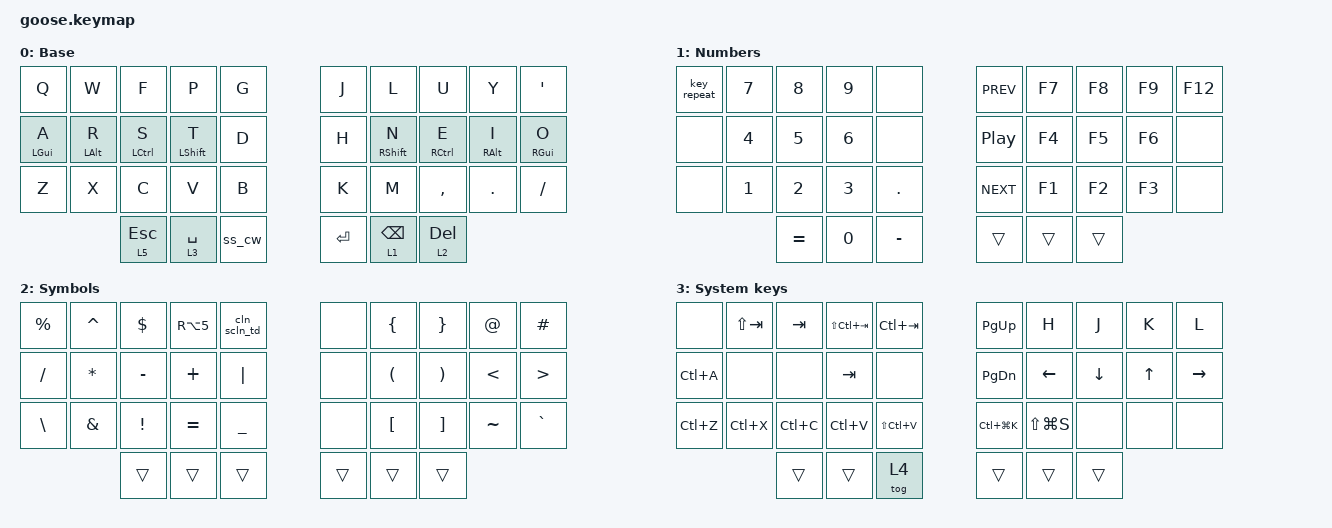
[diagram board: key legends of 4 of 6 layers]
#include <behaviors.dtsi>
#include <dt-bindings/zmk/keys.h>
#include <dt-bindings/zmk/bt.h>

// Home row mods settings

// Speed without triggering modifier
#define TAPPING_RESOLUTION 100

// Hold time for tap-preferred behavior
#define HOLD_TYPE "tap-preferred"

// Time to wait after typing before mods are available
#define STREAK_DECAY (TAPPING_RESOLUTION + 100)

// Time to auto-repeat key
#define REPEAT_DECAY (TAPPING_RESOLUTION + 100)

// Time to trigger layer
#define LAYER_HOLD_TIME (TAPPING_RESOLUTION + 50)

// Time to trigger home row mods
#define HRM_HOLD_TIME (TAPPING_RESOLUTION + 50)

// Time to trigger tap dance
#define TAP_DANCE_TIME (TAPPING_RESOLUTION + 100)

// Idle time before sticky keys are released
#define IDLE_TIMEOUT_MS 7500

&lt {
    // Layer toggle
    flavor = HOLD_TYPE;
    tapping-term-ms = <LAYER_HOLD_TIME>;
    quick-tap-ms = <REPEAT_DECAY>;
};
&sk {
    // Sticky keys settings, One Shot Keys [QMK]

    release-after-ms = <IDLE_TIMEOUT_MS>;
    quick-release;
};
&caps_word {
    // Allow caps word to continue even when minus or underscore are pressed.
    // Also prevent mod presses from cancelling caps word.

    continue-list = <
      UNDERSCORE MINUS
      LCTRL LALT LGUI LSHFT
      RCTRL RALT RGUI RSHFT
      BACKSPACE
    >;

    /delete-property/ ignore-modifiers;
};
/ {
    behaviors {
        hrm: homerow_mods {
            compatible = "zmk,behavior-hold-tap";
            flavor = HOLD_TYPE;

            #binding-cells = <2>;
            bindings = <&kp>, <&kp>;

            tapping-term-ms = <HRM_HOLD_TIME>;
            quick-tap-ms = <REPEAT_DECAY>;
            require-prior-idle-ms = <STREAK_DECAY>;
        };
        hrmralt: homerow_mods_ralt {
            compatible = "zmk,behavior-hold-tap";
            flavor = HOLD_TYPE;

            #binding-cells = <2>;
            bindings = <&kp>, <&kp>;

            tapping-term-ms = <HRM_HOLD_TIME>;
            quick-tap-ms = <REPEAT_DECAY>;
            require-prior-idle-ms = <(TAPPING_RESOLUTION + 25)>;
        };

        ss_cw: shift_capsword {
            compatible = "zmk,behavior-tap-dance";
            #binding-cells = <0>;
            bindings = <&sk LEFT_SHIFT>, <&caps_word>;

            tapping-term-ms = <TAP_DANCE_TIME>;
        };

        cln_scln_td: cln_scln_td {
            compatible = "zmk,behavior-tap-dance";
            #binding-cells = <0>;
            bindings = <&kp COLON>, <&kp SEMICOLON>;
        };

    };

    keymap {
        compatible = "zmk,keymap";

        base {
            display-name = "Base";
            bindings = <
                &kp Q            &kp W            &kp F                &kp P              &kp G   &kp J      &kp L               &kp U                 &kp Y             &kp SINGLE_QUOTE
                &hrm LEFT_GUI A  &hrm LEFT_ALT R  &hrm LEFT_CONTROL S  &hrm LEFT_SHIFT T  &kp D   &kp H      &hrm RIGHT_SHIFT N  &hrm RIGHT_CONTROL E  &hrmralt RIGHT_ALT I  &hrm RIGHT_GUI O
                &kp Z            &kp X            &kp C                &kp V              &kp B   &kp K      &kp M               &kp COMMA            &kp DOT          &kp SLASH
                                                  &lt 5 ESC            &lt 3 SPACE        &ss_cw  &kp ENTER  &lt 1 BACKSPACE     &lt 2 DELETE
            >;

            sensor-bindings =
                <&inc_dec_kp C_VOL_UP C_VOLUME_DOWN>,
                <&inc_dec_kp PG_UP PAGE_DOWN>;
        };

        num_fun {
            display-name = "Numbers";
            bindings = <
                &key_repeat  &kp N7  &kp N8     &kp N9  &none      &kp C_PREV  &kp F7  &kp F8  &kp F9  &kp F12
                &none        &kp N4  &kp N5     &kp N6  &none      &kp C_PP    &kp F4  &kp F5  &kp F6  &none
                &none        &kp N1  &kp N2     &kp N3  &kp DOT    &kp C_NEXT  &kp F1  &kp F2  &kp F3  &none
                                    &kp EQUAL  &kp N0  &kp MINUS  &trans      &trans  &trans
            >;

            sensor-bindings = <&inc_dec_kp LC(Z) LC(Y)>;
        };

        sym_uti {
            display-name = "Symbols";
            bindings = <
                &kp PERCENT  &kp CARET      &kp DOLLAR       &kp RA(N5)  &cln_scln_td    &none   &kp LEFT_BRACE        &kp RIGHT_BRACE        &kp AT_SIGN    &kp HASH
                &kp FSLH     &kp ASTERISK   &kp MINUS        &kp PLUS    &kp PIPE        &none   &kp LEFT_PARENTHESIS  &kp RIGHT_PARENTHESIS  &kp LESS_THAN  &kp GREATER_THAN
                &kp BSLH     &kp AMPERSAND  &kp EXCLAMATION  &kp EQUAL   &kp UNDERSCORE  &none   &kp LBKT              &kp RBKT               &kp TILDE      &kp GRAVE
                                            &trans           &trans      &trans          &trans  &trans                &trans
            >;

            sensor-bindings = <&inc_dec_kp LC(RIGHT_ARROW) LC(LEFT_ARROW)>;
        };

        nav_sys {
            display-name = "System keys";
            bindings = <
                &none      &kp LS(TAB)  &kp TAB    &kp LS(LC(TAB))  &kp LC(TAB)    &kp PG_UP      &kp H          &kp J     &kp K   &kp L
                &kp LC(A)  &none        &none      &kp TAB          &none          &kp PG_DN      &kp LEFT       &kp DOWN  &kp UP  &kp RIGHT
                &kp LC(Z)  &kp LC(X)    &kp LC(C)  &kp LC(V)        &kp LS(LC(V))  &kp LC(LG(K))  &kp LS(LG(S))  &none     &none   &none
                                        &trans     &trans           &tog 4         &trans         &trans         &trans
            >;

        };

        flat {
            display-name = "Flat keyboard";
            bindings = <
              &kp Q  &kp W   &kp F    &kp P      &kp G      &kp J      &kp L          &kp U       &kp Y    &kp LEFT_ALT
              &kp A  &kp R   &kp S    &kp T      &kp D      &kp H      &kp N          &kp E       &kp I    &kp O
              &kp Z  &kp X   &kp C    &kp V      &kp B      &kp K      &kp M          &kp COMMA   &kp DOT  &kp FSLH
                            &kp ESC  &kp SPACE  &kp LSHFT  &kp ENTER  &kp BACKSPACE  &kp DELETE  &tog 4
            >;
        };

        utility {
            display-name = "Utility";
            bindings = <
              &bt BT_CLR_ALL     &none           &none                      &none              &none        &none        &none  &none  &none   &bt BT_CLR_ALL
              &kp LS(LC(LG(E)))  &kp LG(RETURN)  &kp LS(LC(LG(BACKSPACE)))  &kp LS(LC(LG(H)))  &none        &none        &none  &none  &none  &none
              &none              &none           &none                      &none              &sys_reset   &sys_reset   &none  &none  &none  &none
                                &none           &none                      &none              &bootloader  &bootloader  &none  &none  &none
            >;
        };

        extra1 { status = "reserved"; };

        extra2 { status = "reserved"; };

    };
};
